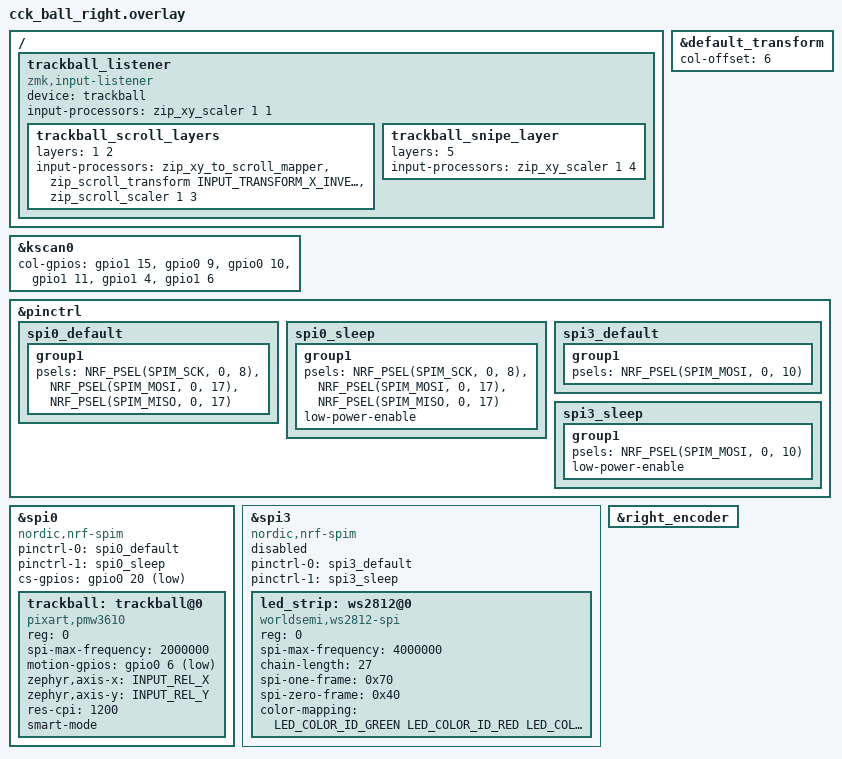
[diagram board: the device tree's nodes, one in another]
/*
 * Copyright (c) 2020 ZMK Contributors
 *
 * SPDX-License-Identifier: MIT
 */
 
#include "cck_ball.dtsi"
#include <input/processors.dtsi>
#include <dt-bindings/zmk/input_transform.h>
#include <zephyr/dt-bindings/input/input-event-codes.h>

&default_transform {
    col-offset = <6>;
}; 

&kscan0 {
	col-gpios
		= <&gpio1 15 GPIO_ACTIVE_HIGH>
        , <&gpio0 9 GPIO_ACTIVE_HIGH>
        , <&gpio0 10 GPIO_ACTIVE_HIGH>
        , <&gpio1 11 GPIO_ACTIVE_HIGH>
        , <&gpio1 4 GPIO_ACTIVE_HIGH>
        , <&gpio1 6 GPIO_ACTIVE_HIGH>
		;
};

// trackball
&pinctrl {
    spi0_default: spi0_default {
        group1 {
            psels = <NRF_PSEL(SPIM_SCK, 0, 8)>,
                <NRF_PSEL(SPIM_MOSI, 0, 17)>,
                <NRF_PSEL(SPIM_MISO, 0, 17)>;
        };
    };

    spi0_sleep: spi0_sleep {
        group1 {
            psels = <NRF_PSEL(SPIM_SCK, 0, 8)>,
                <NRF_PSEL(SPIM_MOSI, 0, 17)>,
                <NRF_PSEL(SPIM_MISO, 0, 17)>;
            low-power-enable;
        };
    };
};

&spi0 {
    status = "okay";
    compatible = "nordic,nrf-spim";
    pinctrl-0 = <&spi0_default>;
    pinctrl-1 = <&spi0_sleep>;
    pinctrl-names = "default", "sleep";
    cs-gpios = <&gpio0 20 GPIO_ACTIVE_LOW>;

    trackball: trackball@0 {
        status = "okay";
        compatible = "pixart,pmw3610";
        reg = <0>;
        spi-max-frequency = <2000000>;
        motion-gpios = <&gpio0 6 (GPIO_ACTIVE_LOW | GPIO_PULL_UP)>;
        zephyr,axis-x = <INPUT_REL_X>;
        zephyr,axis-y = <INPUT_REL_Y>;
        res-cpi = <1200>;
        smart-mode;
      // automouse-layer = <3>;
    };
};


//RGB bus
&pinctrl {
    spi3_default: spi3_default {
        group1 {
            psels = <NRF_PSEL(SPIM_MOSI, 0, 10)>;
        };
    };

    spi3_sleep: spi3_sleep {
        group1 {
            psels = <NRF_PSEL(SPIM_MOSI, 0, 10)>;
            low-power-enable;
        };
    };
};

&spi3 {
    compatible = "nordic,nrf-spim";
    status = "disabled"; // 本键盘没有灯珠 / no LEDs populated on this build

    pinctrl-0 = <&spi3_default>;
    pinctrl-1 = <&spi3_sleep>;
    pinctrl-names = "default", "sleep";

    led_strip: ws2812@0 {
        compatible = "worldsemi,ws2812-spi";

        /* SPI */
        reg = <0>; /* ignored, but necessary for SPI bindings */
        spi-max-frequency = <4000000>;

        /* WS2812 */
        chain-length = <27>; /* number of LEDs */
        spi-one-frame = <0x70>;
        spi-zero-frame = <0x40>;
        color-mapping = <LED_COLOR_ID_GREEN
                         LED_COLOR_ID_RED
                         LED_COLOR_ID_BLUE>;
    };
};



/ {
    trackball_listener: trackball_listener {
        compatible = "zmk,input-listener";
        device = <&trackball>;
        input-processors = <&zip_xy_scaler 1 1>;

        trackball_scroll_layers {
            layers = <1 2>;
            input-processors = <&zip_xy_to_scroll_mapper>,
                               <&zip_scroll_transform INPUT_TRANSFORM_X_INVERT>,
                               // 平滑滚动：16 单位 = 1 档（ZMK 描述符上限，见 hid.h）。
                               // 1200 CPI / 48 = 25 档/英寸；25*16 = 400 单位/英寸，
                               // 400/1200 = 1/3。之前按 120 算成 "5 2"，快了 7.5 倍。
                               // Smooth scrolling: 16 units = 1 detent (ZMK descriptor
                               // caps the Resolution Multiplier at 16, see hid.h).
                               // 1200 CPI / 48 = 25 detents per inch of ball travel;
                               // 25 * 16 = 400 units/inch, and 400/1200 = 1/3.
                               // The earlier "5 2" assumed 120 and ran 7.5x too fast.
                               <&zip_scroll_scaler 1 3>;
        };

        trackball_snipe_layer {
            layers = <5>;
            // 1/4 速，比之前的 1/2 更适合精确瞄准。
            // Quarter speed (was 1 2). The scaler carries a remainder between
            // events, so slow deliberate movement is deferred, never discarded.
            input-processors = <&zip_xy_scaler 1 4>;
        };
    };
};

// enable right encoder
&right_encoder {
	status = "okay";
};
